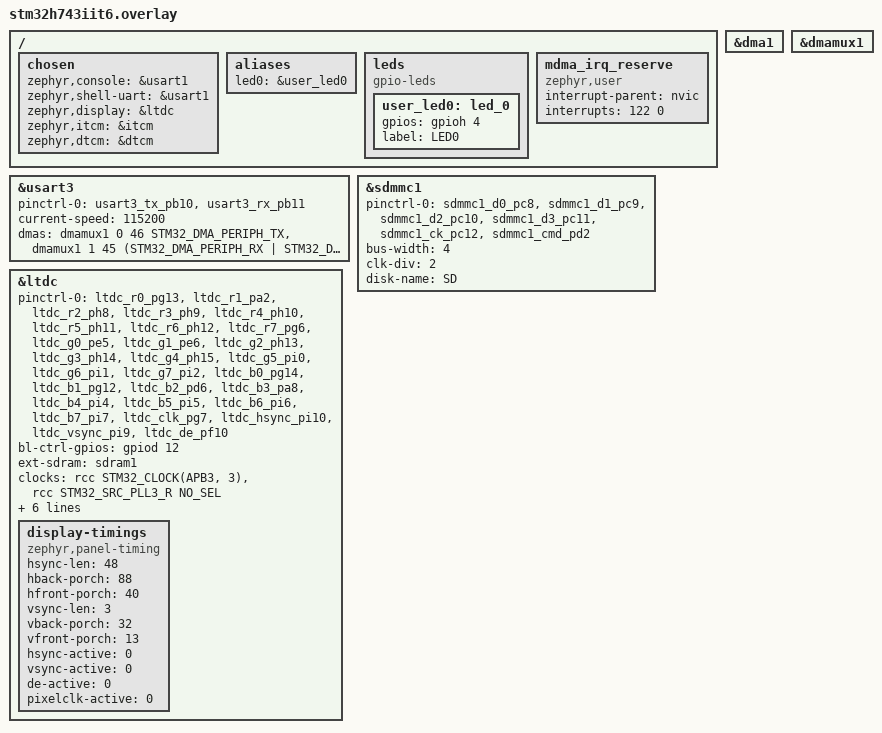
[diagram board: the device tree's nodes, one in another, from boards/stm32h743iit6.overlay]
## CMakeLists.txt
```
cmake_minimum_required(VERSION 3.20.0)
find_package(Zephyr REQUIRED HINTS $ENV{ZEPHYR_BASE})
project(mp3)

# --- lib 驱动源文件 ---
file(GLOB LIB_DRIVER_SOURCES CONFIGURE_DEPENDS
  ${CMAKE_CURRENT_SOURCE_DIR}/lib/*.c
)

# --- app 源文件 ---
file(GLOB APP_SOURCES CONFIGURE_DEPENDS
  ${CMAKE_CURRENT_SOURCE_DIR}/app/*.c
)

# --- bootloader app 源文件 (MCUboot 升级相关) ---
file(GLOB BOOTLOADER_APP_SOURCES CONFIGURE_DEPENDS
  ${CMAKE_CURRENT_SOURCE_DIR}/bootloader/app/*.c
)

# --- bootloader lib 源文件 (MCUboot 辅助库) ---
file(GLOB BOOTLOADER_LIB_SOURCES CONFIGURE_DEPENDS
  ${CMAKE_CURRENT_SOURCE_DIR}/bootloader/lib/*.c
)

# --- hdiffpatch 差分库源文件 ---
file(GLOB HDIFFPATCH_SOURCES CONFIGURE_DEPENDS
  ${CMAKE_CURRENT_SOURCE_DIR}/bootloader/lib/hdiffpatch/*.c
)

# --- 应用源文件 ---
target_sources(app PRIVATE
  src/main.c
  src/led_thread.c
  src/video_thread.c
  ${APP_SOURCES}
  ${LIB_DRIVER_SOURCES}
  ${BOOTLOADER_APP_SOURCES}
  ${BOOTLOADER_LIB_SOURCES}
  ${HDIFFPATCH_SOURCES}
)

# --- 头文件路径 ---
target_include_directories(app PRIVATE
  ${CMAKE_CURRENT_SOURCE_DIR}/lib
  ${CMAKE_CURRENT_SOURCE_DIR}/app
  ${CMAKE_CURRENT_SOURCE_DIR}/bootloader/app
  ${CMAKE_CURRENT_SOURCE_DIR}/bootloader/lib
  ${CMAKE_CURRENT_SOURCE_DIR}/bootloader/lib/hdiffpatch
)

# --- HDiffPatch 编译选项 (单线程嵌入式模式) ---
target_compile_definitions(app PRIVATE
  _IS_USED_MULTITHREAD=0
  _IS_NEED_CACHE_OLD_BY_COVERS=0
  _IS_NEED_CACHE_OLD_ALL=0
)

# ============================================================
# Code/Data Relocation: LVGL hot path -> ITCM + DTCM
# ============================================================
# ITCM (64KB):  LVGL render pipeline hot functions (.text only)
# DTCM (128KB): LVGL BSS (zero-init data, via __section__ attribute)
# NOTE: DMA buffers must NOT go to DTCM (DTCM is not DMA-accessible)
if(CONFIG_CODE_DATA_RELOCATION)
  # Collect LVGL core source files
  file(GLOB_RECURSE LVGL_CORE_SOURCES
    ${ZEPHYR_LVGL_MODULE_DIR}/src/core/*.c
    ${ZEPHYR_LVGL_MODULE_DIR}/src/draw/*.c
    ${ZEPHYR_LVGL_MODULE_DIR}/src/display/*.c
    ${ZEPHYR_LVGL_MODULE_DIR}/src/indev/*.c
    ${ZEPHYR_LVGL_MODULE_DIR}/src/widgets/*.c
    ${ZEPHYR_LVGL_MODULE_DIR}/src/themes/*.c
    ${ZEPHYR_LVGL_MODULE_DIR}/src/layouts/*.c
    ${ZEPHYR_LVGL_MODULE_DIR}/src/font/*.c
    ${ZEPHYR_LVGL_MODULE_DIR}/src/misc/*.c
    ${ZEPHYR_LVGL_MODULE_DIR}/src/others/*.c
    ${ZEPHYR_LVGL_MODULE_DIR}/src/stdlib/*.c
    ${ZEPHYR_LVGL_MODULE_DIR}/src/tick/*.c
    ${ZEPHYR_LVGL_MODULE_DIR}/src/lv_init.c
  )

  # ---- ITCM: LVGL render hot path (.text only) ----
  zephyr_code_relocate(
    FILES ${LVGL_CORE_SOURCES}
    FILTER ".*lv_blend_to_rgb565.*|.*lv_blend_fill.*|.*lv_draw_sw_blend\\b.*|.*lv_draw_sw_fill.*|.*lv_draw_sw_img.*|.*lv_draw_sw_border.*|.*lv_draw_sw_letter.*|.*lv_draw_sw_transform.*|.*lv_draw_sw_mask.*|.*lv_draw_sw_grad.*|.*lv_draw_sw_box_shadow.*|.*lv_draw_sw_arc.*|.*lv_draw_sw_line.*|.*lv_draw_sw_triangle.*|.*lv_draw_sw_vector.*|.*lv_draw_sw_blur.*|.*lv_draw_sw_utils.*|.*lv_draw_sw\\b.*|.*lv_font_fmt_txt.*|.*lv_image_decoder.*|.*lv_draw_label.*|.*lv_draw_image.*|.*lv_draw_rect.*|.*lv_draw_arc.*|.*lv_draw_line.*|.*lv_draw_mask.*|.*lv_draw_blur.*|.*lv_draw_triangle.*|.*lv_draw_vector.*|.*lv_area\\b.*|.*lv_refr\\b.*|.*lv_draw_buf\\b.*|.*lv_display_flush.*"
    LOCATION ITCM
  )
endif()
```

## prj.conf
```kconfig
# ============================================================
# Project: STM32H743IIT6 LVGL + MCUboot Application
# Board:  stm32h743iit6
# ============================================================

# ============================================================
# 1. Platform Core
# ============================================================
CONFIG_FPU=y
CONFIG_SPEED_OPTIMIZATIONS=y
CONFIG_MAIN_STACK_SIZE=4096

# ============================================================
# 2. Logging & Debug
# ============================================================
CONFIG_LOG=y
CONFIG_LOG_BUFFER_SIZE=4096
CONFIG_STM32_ENABLE_DEBUG_SLEEP_STOP=y
# ============================================================
# 3. Console & Shell
# ============================================================
CONFIG_PRINTK=y
CONFIG_CONSOLE=y
CONFIG_UART_CONSOLE=y
CONFIG_SHELL=y
CONFIG_SHELL_BACKEND_SERIAL=y
CONFIG_FILE_SYSTEM_SHELL=y

# ============================================================
# 4. Peripheral Drivers
# ============================================================
CONFIG_SERIAL=y
CONFIG_GPIO=y
CONFIG_DMA=y
CONFIG_DMA_INIT_PRIORITY=30
CONFIG_DMAMUX_STM32_INIT_PRIORITY=31

# ============================================================
# 5. Display (LTDC + SDRAM)
# ============================================================
CONFIG_DISPLAY=y
CONFIG_STM32_LTDC_RGB565=y
CONFIG_STM32_LTDC_FB_NUM=1

CONFIG_MEMC=y
CONFIG_MEMC_STM32=y
CONFIG_MEMC_STM32_SDRAM=y

# ============================================================
# 6. SD Card & FAT Filesystem
# ============================================================
CONFIG_DISK_ACCESS=y
CONFIG_FILE_SYSTEM=y
CONFIG_FILE_SYSTEM_MKFS=y
CONFIG_FILE_SYSTEM_MAX_FILE_NAME=255

CONFIG_FAT_FILESYSTEM_ELM=y
CONFIG_FS_FATFS_LFN=y
CONFIG_FS_FATFS_LFN_MODE_HEAP=y
CONFIG_FS_FATFS_MAX_LFN=255

CONFIG_SDMMC_STM32_HWFC=y
CONFIG_SDMMC_STM32_CLOCK_CHECK=n

# ============================================================
# 7. LVGL (Zephyr Module, v9.x)
# ============================================================
CONFIG_LVGL=y
CONFIG_LV_COLOR_DEPTH_16=y
CONFIG_LV_Z_MEM_POOL_SIZE=65535
CONFIG_LV_DEF_REFR_PERIOD=16

# -- Double VDB (tear-free rendering) --
CONFIG_LV_Z_DOUBLE_VDB=y
CONFIG_LV_Z_VDB_SIZE=10

# -- Performance monitoring --
CONFIG_LV_USE_SYSMON=y
CONFIG_LV_USE_PERF_MONITOR=y

# ----------------------------------------------------------
# 7a. LVGL Fonts (keep only montserrat_14)
# ----------------------------------------------------------
CONFIG_LV_FONT_MONTSERRAT_8=n
CONFIG_LV_FONT_MONTSERRAT_10=n
CONFIG_LV_FONT_MONTSERRAT_12=n
CONFIG_LV_FONT_MONTSERRAT_16=n
CONFIG_LV_FONT_MONTSERRAT_18=n
CONFIG_LV_FONT_MONTSERRAT_20=n
CONFIG_LV_FONT_MONTSERRAT_22=n
CONFIG_LV_FONT_MONTSERRAT_24=n
CONFIG_LV_FONT_MONTSERRAT_26=n
CONFIG_LV_FONT_MONTSERRAT_28=n
CONFIG_LV_FONT_MONTSERRAT_30=n
CONFIG_LV_FONT_MONTSERRAT_32=n
CONFIG_LV_FONT_MONTSERRAT_34=n
CONFIG_LV_FONT_MONTSERRAT_36=n
CONFIG_LV_FONT_MONTSERRAT_38=n
CONFIG_LV_FONT_MONTSERRAT_40=n
CONFIG_LV_FONT_MONTSERRAT_42=n
CONFIG_LV_FONT_MONTSERRAT_44=n
CONFIG_LV_FONT_MONTSERRAT_46=n
CONFIG_LV_FONT_MONTSERRAT_48=n
CONFIG_LV_FONT_UNSCII_8=n
CONFIG_LV_FONT_UNSCII_16=n
CONFIG_LV_FONT_DEJAVU_16_PERSIAN_HEBREW=n
CONFIG_LV_FONT_SOURCE_HAN_SANS_SC_14_CJK=n
CONFIG_LV_FONT_SOURCE_HAN_SANS_SC_16_CJK=n

# ----------------------------------------------------------
# 7b. LVGL Widgets (keep: button, label, image, slider,
#     list, switch, bar, arc, textarea)
# ----------------------------------------------------------
CONFIG_LV_USE_ANIMIMG=n
CONFIG_LV_USE_ARCLABEL=n
CONFIG_LV_USE_CALENDAR=n
CONFIG_LV_USE_CALENDAR_HEADER_ARROW=n
CONFIG_LV_USE_CALENDAR_HEADER_DROPDOWN=n
CONFIG_LV_USE_CANVAS=n
CONFIG_LV_USE_CHART=n
CONFIG_LV_USE_CHECKBOX=n
CONFIG_LV_USE_DROPDOWN=n
CONFIG_LV_USE_IMAGEBUTTON=n
CONFIG_LV_USE_KEYBOARD=n
CONFIG_LV_USE_LED=n
CONFIG_LV_USE_LINE=n
CONFIG_LV_USE_MENU=n
CONFIG_LV_USE_MSGBOX=n
CONFIG_LV_USE_ROLLER=n
CONFIG_LV_USE_SCALE=n
CONFIG_LV_USE_SPAN=n
CONFIG_LV_USE_SPINBOX=n
CONFIG_LV_USE_SPINNER=n
CONFIG_LV_USE_TABLE=n
CONFIG_LV_USE_TABVIEW=n
CONFIG_LV_USE_TILEVIEW=n
CONFIG_LV_USE_WIN=n

# ----------------------------------------------------------
# 7c. LVGL Themes (keep only default)
# ----------------------------------------------------------
CONFIG_LV_USE_THEME_SIMPLE=n

# ----------------------------------------------------------
# 7d. LVGL Libraries (none needed)
# ----------------------------------------------------------
CONFIG_LV_USE_BARCODE=n
CONFIG_LV_USE_BMP=n
CONFIG_LV_USE_GIF=n
CONFIG_LV_USE_FFMPEG=n
CONFIG_LV_USE_FREETYPE=n
CONFIG_LV_USE_LODEPNG=n
CONFIG_LV_USE_LIBPNG=n
CONFIG_LV_USE_LIBJPEG_TURBO=n
CONFIG_LV_USE_LIBWEBP=n
CONFIG_LV_USE_TJPGD=n
CONFIG_LV_USE_TINY_TTF=n
CONFIG_LV_USE_QRCODE=n
CONFIG_LV_USE_RLOTTIE=n
CONFIG_LV_USE_SVG=n
CONFIG_LV_USE_LZ4=n
CONFIG_LV_USE_RLE=n

# ----------------------------------------------------------
# 7e. LVGL Filesystem Drivers (use Zephyr FATFS directly)
# ----------------------------------------------------------
CONFIG_LV_USE_FS_FATFS=n
CONFIG_LV_USE_FS_STDIO=n
CONFIG_LV_USE_FS_POSIX=n
CONFIG_LV_USE_FS_WIN32=n
CONFIG_LV_USE_FS_MEMFS=n
CONFIG_LV_USE_FS_LITTLEFS=n

# ----------------------------------------------------------
# 7f. LVGL GPU Backends (only DMA2D + SW needed)
# ----------------------------------------------------------
CONFIG_LV_USE_DRAW_EVE=n
CONFIG_LV_USE_DRAW_VG_LITE=n
CONFIG_LV_USE_DRAW_SDL=n
CONFIG_LV_USE_DRAW_DAVE2D=n
CONFIG_LV_USE_PXP=n
CONFIG_LV_USE_G2D=n
CONFIG_LV_USE_PPA=n
CONFIG_LV_USE_DRAW_OPENGLES=n

# ----------------------------------------------------------
# 7g. LVGL Debug / Misc (not needed)
# ----------------------------------------------------------
CONFIG_LV_USE_MONKEY=n
CONFIG_LV_USE_TEST=n
CONFIG_LV_USE_FILE_EXPLORER=n
CONFIG_LV_USE_FRAGMENT=n
CONFIG_LV_USE_GRIDNAV=n
CONFIG_LV_USE_IME_PINYIN=n
CONFIG_LV_USE_LOTTIE=n
CONFIG_LV_USE_3DTEXTURE=n
CONFIG_LV_USE_OBJ_PROPERTY=n

# ============================================================
# 8. UART OTA (YModem Protocol, DMA-based)
# ============================================================
CONFIG_UART_ASYNC_API=y
CONFIG_NOCACHE_MEMORY=y
CONFIG_RING_BUFFER=y

# ============================================================
# 9. MCUboot Bootloader & Firmware Upgrade
# ============================================================
CONFIG_BOOTLOADER_MCUBOOT=y
CONFIG_IMG_MANAGER=y
CONFIG_MCUBOOT_BOOTUTIL_LIB=y
CONFIG_USE_DT_CODE_PARTITION=y

# -- Flash operations --
CONFIG_FLASH=y
CONFIG_FLASH_PAGE_LAYOUT=y
CONFIG_FLASH_MAP=y
CONFIG_STREAM_FLASH=y
CONFIG_MPU_ALLOW_FLASH_WRITE=y

# -- Utilities --
CONFIG_CRC=y
CONFIG_REBOOT=y
CONFIG_HEAP_MEM_POOL_SIZE=16384

# ============================================================
# 10. Code/Data Relocation: LVGL hot path -> ITCM + DTCM
# ============================================================
# ITCM (64KB):  LVGL render pipeline hot functions
# DTCM (128KB): LVGL BSS (zero-init data)
# NOTE: DMA buffers must NOT go to DTCM (DTCM is not DMA-accessible)
CONFIG_CODE_DATA_RELOCATION=y
```

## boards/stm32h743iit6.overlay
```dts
/ {
	chosen {
		zephyr,console = &usart1;
		zephyr,shell-uart = &usart1;
		zephyr,display = &ltdc;
		zephyr,itcm = &itcm;
		zephyr,dtcm = &dtcm;
	};

	aliases {
		led0 = &user_led0;
	};

	leds {
		compatible = "gpio-leds";

		user_led0: led_0 {
			gpios = <&gpioh 4 GPIO_ACTIVE_HIGH>;
			label = "LED0";
		};
	};

	/* MDMA 中断保留 (JPEG 硬件解码使用) */
	mdma_irq_reserve {
		compatible = "zephyr,user";
		interrupt-parent = <&nvic>;
		interrupts = <122 0>;
		status = "okay";
	};
};

&usart3 {
	pinctrl-0 = <&usart3_tx_pb10 &usart3_rx_pb11>;

	pinctrl-names = "default";
	current-speed = <115200>;
	dmas = <&dmamux1 0 46 STM32_DMA_PERIPH_TX>,
		   <&dmamux1 1 45 (STM32_DMA_PERIPH_RX | STM32_DMA_MODE_CYCLIC)>;
	dma-names = "tx", "rx";
	status = "okay";
};

&dma1 {
	status = "okay";
};

&dmamux1 {
	status = "okay";
};

&sdmmc1 {
	status = "okay";
	pinctrl-0 = <&sdmmc1_d0_pc8 &sdmmc1_d1_pc9
				 &sdmmc1_d2_pc10 &sdmmc1_d3_pc11
				 &sdmmc1_ck_pc12 &sdmmc1_cmd_pd2>;
	pinctrl-names = "default";

	bus-width = <4>;
	clk-div = <2>;
	disk-name = "SD";
};

&ltdc {
	pinctrl-0 = <&ltdc_r0_pg13 &ltdc_r1_pa2 &ltdc_r2_ph8 &ltdc_r3_ph9
				 &ltdc_r4_ph10 &ltdc_r5_ph11 &ltdc_r6_ph12 &ltdc_r7_pg6
				 &ltdc_g0_pe5 &ltdc_g1_pe6 &ltdc_g2_ph13 &ltdc_g3_ph14
				 &ltdc_g4_ph15 &ltdc_g5_pi0 &ltdc_g6_pi1 &ltdc_g7_pi2
				 &ltdc_b0_pg14 &ltdc_b1_pg12 &ltdc_b2_pd6 &ltdc_b3_pa8
				 &ltdc_b4_pi4 &ltdc_b5_pi5 &ltdc_b6_pi6 &ltdc_b7_pi7
				 &ltdc_clk_pg7 &ltdc_hsync_pi10 &ltdc_vsync_pi9 &ltdc_de_pf10>;
	pinctrl-names = "default";
	bl-ctrl-gpios = <&gpiod 12 GPIO_ACTIVE_HIGH>;
	ext-sdram = <&sdram1>;
	clocks = <&rcc STM32_CLOCK(APB3, 3)>, <&rcc STM32_SRC_PLL3_R NO_SEL>;
	status = "okay";

	width = <800>;
	height = <480>;
	pixel-format = <PANEL_PIXEL_FORMAT_RGB_888>;

	display-timings {
		compatible = "zephyr,panel-timing";
		hsync-len = <48>;
		hback-porch = <88>;
		hfront-porch = <40>;
		vsync-len = <3>;
		vback-porch = <32>;
		vfront-porch = <13>;
		hsync-active = <0>;
		vsync-active = <0>;
		de-active = <0>;
		pixelclk-active = <0>;
	};

	def-back-color-red = <0x00>;
	def-back-color-green = <0x00>;
	def-back-color-blue = <0xff>;
};
```

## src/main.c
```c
#include "main.h"
#include "led_thread.h"
#include "video_thread.h"

LOG_MODULE_REGISTER(main, LOG_LEVEL_INF);

/* SD 卡文件系统 */
static FATFS g_sd_fatfs;
static struct fs_mount_t sd_mount = {
    .type = FS_FATFS,
    .mnt_point = "/SD:",
    .fs_data = &g_sd_fatfs,
};

/* SD 卡自动挂载 */
static int sdcard_auto_mount(void)
{
    static const char *disk = "SD";
    int ret;
    for (int i = 0; i < 5; i++)
    {
        ret = disk_access_init(disk);
        if (ret == 0)
            break;
        k_sleep(K_MSEC(100));
    }
    if (ret != 0)
    {
        LOG_ERR("disk_access_init failed (%d)", ret);
        return ret;
    }
    ret = fs_mount(&sd_mount);
    if (ret != 0)
    {
        LOG_ERR("fs_mount failed (%d)", ret);
        return ret;
    }
    LOG_INF("mounted at /SD:");
    return 0;
}

int main(void)
{
    /* ========== 主线程：基础硬件初始化 ========== */
    my_heap_init();
    sdcard_auto_mount();

    /* ========== 创建所有子线程（K_FOREVER 挂起，暂不调度） ========== */

    /* LED闪烁线程 */
    if (led_thread_init() != 0)
    {
        LOG_ERR("led_thread_init failed!");
        return -1;
    }

    /* LVGL 显示线程 */
    if (video_thread_init() != 0)
    {
        LOG_ERR("video_thread_init failed!");
        return -1;
    }

    /* ========== 统一启动所有子线程，确保同步开始调度 ========== */
    LOG_INF("starting all threads...");
    led_thread_start();
    video_thread_start();

    /* 主线程退出，子线程继续运行 */
    LOG_INF("init done, exiting");
    return 0;
}
```

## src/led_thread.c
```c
#include "led_thread.h"

#include <zephyr/kernel.h>
#include <zephyr/logging/log.h>
#include <zephyr/drivers/gpio.h>
#include <zephyr/devicetree.h>

LOG_MODULE_REGISTER(led_thread, LOG_LEVEL_INF);

/* LED 设备树节点 */
#define LED0_NODE DT_ALIAS(led0)
#define LED1_NODE DT_ALIAS(led1)

/* 线程栈和线程数据结构（栈放置在 DTCM 区域） */
__attribute__((__section__("DTCM"))) static char led_thread_stack[LED_THREAD_STACK_SIZE];
static struct k_thread led_thread_data;
static k_tid_t led_thread_id;

/* LED 设备规格 */
static const struct gpio_dt_spec led0 = GPIO_DT_SPEC_GET(LED0_NODE, gpios);

/* LED闪烁线程入口函数 */
static void led_thread_entry(void *arg1, void *arg2, void *arg3)
{
    bool led_state = true;

    LOG_INF("started");

    while (1)
    {
        /* 翻转 LED0 和 LED1 */
        led_state = !led_state;

        gpio_pin_set_dt(&led0, led_state ? 1 : 0);

        k_sleep(K_MSEC(LED_BLINK_INTERVAL_MS));
    }
}

/* LED闪烁线程初始化（含GPIO初始化） */
int led_thread_init(void)
{
    /* 初始化 GPIO */
    gpio_pin_configure_dt(&led0, GPIO_OUTPUT_ACTIVE);

    /* 创建线程（暂不启动） */
    led_thread_id = k_thread_create(&led_thread_data,
                                    (k_thread_stack_t *)led_thread_stack,
                                    LED_THREAD_STACK_SIZE,
                                    led_thread_entry,
                                    NULL, NULL, NULL,
                                    LED_THREAD_PRIORITY,
                                    0,
                                    K_FOREVER);

    if (led_thread_id == NULL)
    {
        LOG_ERR("create failed");
        return -1;
    }

    /* 设置线程名（调试/Shell 中可见） */
    k_thread_name_set(led_thread_id, "led");

    LOG_INF("initialized");
    return 0;
}

/* 启动LED闪烁线程 */
void led_thread_start(void)
{
    k_thread_start(led_thread_id);
}

/* 获取线程ID */
k_tid_t led_thread_get_id(void)
{
    return led_thread_id;
}
```

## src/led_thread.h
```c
#ifndef __LED_THREAD_H__
#define __LED_THREAD_H__

#include <zephyr/kernel.h>

/* LED闪烁线程栈大小 */
#define LED_THREAD_STACK_SIZE 1024

/* LED闪烁线程优先级 */
#define LED_THREAD_PRIORITY 10

/* LED闪烁间隔（毫秒） */
#define LED_BLINK_INTERVAL_MS 500

/* 获取LED线程ID */
k_tid_t led_thread_get_id(void);

/* LED闪烁线程初始化（含GPIO初始化，创建线程但不启动） */
int led_thread_init(void);

/* 启动LED闪烁线程 */
void led_thread_start(void);

#endif /* __LED_THREAD_H__ */
```

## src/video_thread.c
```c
#include "video_thread.h"

#include <zephyr/kernel.h>
#include <zephyr/logging/log.h>
#include <zephyr/drivers/display.h>
#include <zephyr/devicetree.h>

#include <lvgl.h>
#include <lvgl_zephyr.h>

#include "lcd.h"
#include "gt1151q.h"
#include "my_malloc.h"
#include "jpegcodec.h"
#include "lvgl_sd_video.h"
#include "lvgl_sd_pic.h"
#include "lvgl_sd_ota.h"
#include "lvgl_uart_ota.h"
#include "lvgl_firmware_upgrade.h"
#include "lvgl_flush_test.h"

LOG_MODULE_REGISTER(video_thread, LOG_LEVEL_INF);

/* 线程栈和线程数据结构（栈放置在 DTCM 区域） */
__attribute__((__section__("DTCM"))) static char video_thread_stack[VIDEO_THREAD_STACK_SIZE];
static struct k_thread video_thread_data;
static k_tid_t video_thread_id;

/* ── 触摸轮询间隔（毫秒），独立于 LVGL 刷新周期 ────────────── */
#define TOUCH_POLL_INTERVAL_MS 20

/* ── LVGL 触摸 indev 读回调 ────────────────────────────────── */
static lv_indev_t *touch_indev;
static uint32_t last_touch_read_ms;
static lv_coord_t last_x;
static lv_coord_t last_y;
static lv_indev_state_t last_state;

static void touch_read_cb(lv_indev_t *indev, lv_indev_data_t *data)
{
    GT1151Q_Data_t *touch = (GT1151Q_Data_t *)lv_indev_get_user_data(indev);

    /* 节流：控制实际 I2C 读取频率 */
    uint32_t now = lv_tick_get();
    if (now - last_touch_read_ms < TOUCH_POLL_INTERVAL_MS)
    {
        /* 未到轮询间隔，返回上一次状态（保证滑动连续） */
        data->point.x = last_x;
        data->point.y = last_y;
        data->state = last_state;
        return;
    }
    last_touch_read_ms = now;

    if (GT1151Q_ReadData(touch) == GT1151Q_OK && touch->count > 0U)
    {
        GT1151Q_TransformToScreen(touch);
        last_x = (lv_coord_t)touch->points[0].x;
        last_y = (lv_coord_t)touch->points[0].y;
        last_state = LV_INDEV_STATE_PRESSED;
    }
    else
    {
        last_state = LV_INDEV_STATE_RELEASED;
    }

    data->point.x = last_x;
    data->point.y = last_y;
    data->state = last_state;
}

/* ── 触摸初始化 ──*/
static void touch_init(void)
{
    GT1151Q_Status_e st = GT1151Q_Init();
    if (st != GT1151Q_OK)
    {
        LOG_ERR("GT1151Q init failed: %d", st);
        return;
    }

    /* 读取产品 ID 确认设备 */
    char pid[5];
    if (GT1151Q_ReadProductID(pid) == GT1151Q_OK)
    {
        LOG_INF("GT1151Q product ID: %c%c%c%c", pid[0], pid[1], pid[2], pid[3]);
    }

    /* 创建 LVGL pointer indev */
    touch_indev = lv_indev_create();
    if (touch_indev == NULL)
    {
        LOG_ERR("lv_indev_create failed");
        return;
    }

    lv_indev_set_type(touch_indev, LV_INDEV_TYPE_POINTER);
    lv_indev_set_read_cb(touch_indev, touch_read_cb);
    lv_indev_set_user_data(touch_indev, (void *)&Touch_dev);

    /* 绑定到默认 display */
    lv_indev_set_display(touch_indev, lv_display_get_default());

    LOG_INF("GT1151Q touch indev registered");
}

/* ── 主菜单 screen ────────────────────────────────────────── */
static lv_obj_t *g_main_menu_scr = NULL;

/* ============================================================
 * 主菜单界面
 * ============================================================ */

static void show_main_menu(void)
{
    /* 删除旧主菜单释放内存 */
    if (g_main_menu_scr != NULL)
    {
        lv_obj_del(g_main_menu_scr);
        g_main_menu_scr = NULL;
    }

    g_main_menu_scr = lv_obj_create(NULL);
    lv_obj_set_style_bg_color(g_main_menu_scr, lv_color_hex(0x101020), 0);
    lv_obj_set_style_pad_all(g_main_menu_scr, 0, 0);

    /* 背景图片 */
    const lv_image_dsc_t *bg_img = lvgl_sd_pic_get_image();
    if (bg_img != NULL && bg_img->data != NULL)
    {
        lv_obj_t *bg = lv_image_create(g_main_menu_scr);
        lv_image_set_src(bg, bg_img);
        lv_obj_set_size(bg, LV_PCT(100), LV_PCT(100));
        lv_obj_align(bg, LV_ALIGN_CENTER, 0, 0);
        lv_obj_set_style_img_opa(bg, LV_OPA_30, 0);
        lv_obj_move_to_index(bg, 0);
    }

    /* 标题 */
    lv_obj_t *title = lv_label_create(g_main_menu_scr);
    lv_label_set_text(title, "Main Menu");
    lv_obj_set_style_text_color(title, lv_color_white(), 0);
    lv_obj_align(title, LV_ALIGN_TOP_MID, 0, 20);

    /* 固件升级界面按钮 (统一入口) */
    lv_obj_t *fw_btn = lv_button_create(g_main_menu_scr);
    lv_obj_set_size(fw_btn, 200, 50);
    lv_obj_align(fw_btn, LV_ALIGN_CENTER, 0, -60);
    lv_obj_add_event_cb(fw_btn, (lv_event_cb_t)lvgl_firmware_upgrade_start_cb, LV_EVENT_CLICKED, NULL);
    lv_obj_t *fw_lbl = lv_label_create(fw_btn);
    lv_label_set_text(fw_lbl, "Firmware Upgrade");
    lv_obj_center(fw_lbl);

    /* 视频播放界面按钮 */
    lv_obj_t *video_btn = lv_button_create(g_main_menu_scr);
    lv_obj_set_size(video_btn, 200, 50);
    lv_obj_align(video_btn, LV_ALIGN_CENTER, 0, 0);
    lv_obj_add_event_cb(video_btn, (lv_event_cb_t)lvgl_sd_video_start, LV_EVENT_CLICKED, NULL);
    lv_obj_t *video_lbl = lv_label_create(video_btn);
    lv_label_set_text(video_lbl, "Video Player");
    lv_obj_center(video_lbl);

    /* 刷新测试按钮 */
    lv_obj_t *flush_btn = lv_button_create(g_main_menu_scr);
    lv_obj_set_size(flush_btn, 200, 50);
    lv_obj_align(flush_btn, LV_ALIGN_CENTER, 0, 60);
    lv_obj_add_event_cb(flush_btn, (lv_event_cb_t)lvgl_flush_test_start, LV_EVENT_CLICKED, NULL);
    lv_obj_t *flush_lbl = lv_label_create(flush_btn);
    lv_label_set_text(flush_lbl, "Flush Test");
    lv_obj_center(flush_lbl);

    lv_screen_load(g_main_menu_scr);
}

/* video 线程入口函数 */
static void video_thread_entry(void *arg1, void *arg2, void *arg3)
{
    LOG_INF("video thread started");

    /* 注册视频界面的返回主菜单回调 */
    lvgl_sd_video_set_back_to_menu_cb((lv_event_cb_t)show_main_menu);

    /* 注册 OTA 界面的返回回调 - 返回到统一固件升级界面 */
    lvgl_sd_ota_set_back_to_menu_cb((lv_event_cb_t)lvgl_firmware_upgrade_start_cb);

    /* 注册串口 OTA 界面的返回回调 - 返回到统一固件升级界面 */
    lvgl_uart_ota_set_back_to_menu_cb((lv_event_cb_t)lvgl_firmware_upgrade_start_cb);

    /* 注册统一固件升级界面的返回主菜单回调 */
    lvgl_firmware_upgrade_set_back_to_menu_cb((lv_event_cb_t)show_main_menu);

    /* 注册刷新测试页面的返回主菜单回调 */
    lvgl_flush_test_set_back_cb((lv_event_cb_t)show_main_menu);

    /* 显示主菜单 */
    show_main_menu();

    /* LVGL 主循环 */
    while (1)
    {
        lv_timer_handler();
        lvgl_sd_ota_progress_refresh();
        lvgl_uart_ota_progress_refresh();
        k_msleep(LVGL_HANDLER_INTERVAL_MS);
    }
}

/* video 线程初始化 */
int video_thread_init(void)
{
    const struct device *display_dev;

    /* 获取显示设备 */
    display_dev = DEVICE_DT_GET(DT_CHOSEN(zephyr_display));
    if (!device_is_ready(display_dev))
    {
        LOG_ERR("display device not ready");
        return -1;
    }

    /* 打开 LCD 显示（Zephyr LTDC + LVGL 驱动已接管 framebuffer） */
    display_blanking_off(display_dev);

    /* 初始化触摸 */
    touch_init();

    /* 创建线程（暂不启动，K_FOREVER 挂起） */
    video_thread_id = k_thread_create(&video_thread_data,
                                      (k_thread_stack_t *)video_thread_stack,
                                      VIDEO_THREAD_STACK_SIZE,
                                      video_thread_entry,
                                      (void *)display_dev, NULL, NULL,
                                      VIDEO_THREAD_PRIORITY,
                                      0,
                                      K_FOREVER);

    if (video_thread_id == NULL)
    {
        LOG_ERR("create failed");
        return -1;
    }

    /* 设置线程名（调试/Shell 中可见） */
    k_thread_name_set(video_thread_id, "video");

    LOG_INF("initialized");
    return 0;
}

/* 启动 video 线程 */
void video_thread_start(void)
{
    k_thread_start(video_thread_id);
}

/* 获取线程 ID */
k_tid_t video_thread_get_id(void)
{
    return video_thread_id;
}
```

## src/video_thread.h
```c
#ifndef __VIDEO_THREAD_H__
#define __VIDEO_THREAD_H__

#include <zephyr/kernel.h>

/* video 线程栈大小 */
#define VIDEO_THREAD_STACK_SIZE 32768

/* video 线程优先级 */
#define VIDEO_THREAD_PRIORITY 7

/* lv_timer_handler 调用间隔（毫秒） */
#define LVGL_HANDLER_INTERVAL_MS 5

/* 获取 video 线程 ID */
k_tid_t video_thread_get_id(void);

/* video 线程初始化（创建线程但不启动） */
int video_thread_init(void);

/* 启动 video 线程 */
void video_thread_start(void);

#endif /* __VIDEO_THREAD_H__ */
```
